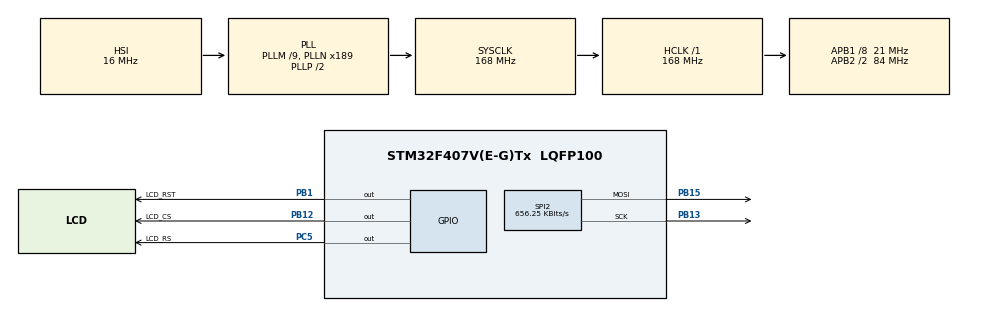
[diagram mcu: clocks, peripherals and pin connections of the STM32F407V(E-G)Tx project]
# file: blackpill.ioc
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Mcu.Family=STM32F4
Mcu.Name=STM32F407V(E-G)Tx
Mcu.Package=LQFP100
NVIC.PriorityGroup=NVIC_PRIORITYGROUP_4
NVIC.TIM8_TRG_COM_TIM14_IRQn=true\:15\:0\:false\:false\:true\:false\:true\:true
NVIC.TimeBase=TIM8_TRG_COM_TIM14_IRQn
NVIC.TimeBaseIP=TIM14
PB1.GPIO_Label=LCD_RST
PB1.GPIO_Speed=GPIO_SPEED_FREQ_VERY_HIGH
PB1.Signal=GPIO_Output
PB12.GPIO_Label=LCD_CS
PB12.GPIO_Speed=GPIO_SPEED_FREQ_VERY_HIGH
PB12.Signal=GPIO_Output
PB13.Mode=TX_Only_Simplex_Unidirect_Master
PB13.Signal=SPI2_SCK
PB15.Mode=TX_Only_Simplex_Unidirect_Master
PB15.Signal=SPI2_MOSI
PC5.GPIO_Label=LCD_RS
PC5.GPIO_Speed=GPIO_SPEED_FREQ_VERY_HIGH
PC5.Signal=GPIO_Output
ProjectManager.HeapSize=0x200
ProjectManager.StackSize=0x400
ProjectManager.TargetToolchain=STM32CubeIDE
RCC.48MHZClocksFreq_Value=84000000
RCC.AHBFreq_Value=168000000
RCC.APB1CLKDivider=RCC_HCLK_DIV8
RCC.APB1Freq_Value=21000000
RCC.APB1TimFreq_Value=42000000
RCC.APB2CLKDivider=RCC_HCLK_DIV2
RCC.APB2Freq_Value=84000000
RCC.APB2TimFreq_Value=168000000
RCC.CortexFreq_Value=168000000
RCC.HCLKFreq_Value=168000000
RCC.HSE_VALUE=25000000
RCC.HSI_VALUE=16000000
RCC.LSE_VALUE=32768
RCC.PLLM=9
RCC.PLLN=189
RCC.SYSCLKFreq_VALUE=168000000
RCC.SYSCLKSource=RCC_SYSCLKSOURCE_PLLCLK
RCC.VCOOutputFreq_Value=336000000
SPI2.BaudRatePrescaler=SPI_BAUDRATEPRESCALER_32
SPI2.CLKPolarity=SPI_POLARITY_LOW
SPI2.CalculateBaudRate=656.25 KBits/s
SPI2.Direction=SPI_DIRECTION_2LINES
SPI2.FirstBit=SPI_FIRSTBIT_MSB
SPI2.Mode=SPI_MODE_MASTER
SPI2.VirtualType=VM_MASTER
VP_SYS_VS_tim14.Mode=TIM14
VP_TIM13_VS_ClockSourceINT.Mode=Enable_Timer
board=custom

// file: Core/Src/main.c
/* USER CODE BEGIN Header */
/**
  ******************************************************************************
  * @file           : main.c
  * @brief          : Main program body
  ******************************************************************************
  * @attention
  *
  * Copyright (c) 2022 STMicroelectronics.
  * All rights reserved.
  *
  * This software is licensed under terms that can be found in the LICENSE file
  * in the root directory of this software component.
  * If no LICENSE file comes with this software, it is provided AS-IS.
  *
  ******************************************************************************
  */
/* USER CODE END Header */
#include "main.h"
#include "spi.h"
#include "tim.h"
#include "gpio.h"

/* USER CODE BEGIN Includes */
#include "st7735.h"
#include "fonts.h"
#include "stdlib.h"
/* USER CODE END Includes */

void SystemClock_Config(void);

int main(void)
{

  /* MCU Configuration--------------------------------------------------------*/

  /* Reset of all peripherals, Initializes the Flash interface and the Systick. */
  HAL_Init();

  /* Configure the system clock */
  SystemClock_Config();

  /* Initialize all configured peripherals */
  MX_GPIO_Init();
  MX_TIM13_Init();
  MX_SPI2_Init();
  /* USER CODE BEGIN 2 */

  ST7735_Init();
  ST7735_FillScreen(ST7735_RED);
  /* USER CODE END 2 */

  /* Infinite loop */
  /* USER CODE BEGIN WHILE */
  uint8_t n = 0;
  char str[10] = { 0 };
  while (1)
  {
    /* USER CODE END WHILE */
    /* USER CODE BEGIN 3 */
	  itoa(n,str,10);
	  ST7735_WriteString(0, 0, str, Font_11x18, ST7735_BLACK, ST7735_WHITE);
	  n++;
  }
  /* USER CODE END 3 */
}

void SystemClock_Config(void)
{
  RCC_OscInitTypeDef RCC_OscInitStruct = {0};
  RCC_ClkInitTypeDef RCC_ClkInitStruct = {0};

  /** Configure the main internal regulator output voltage
  */
  __HAL_RCC_PWR_CLK_ENABLE();
  __HAL_PWR_VOLTAGESCALING_CONFIG(PWR_REGULATOR_VOLTAGE_SCALE1);

  /** Initializes the RCC Oscillators according to the specified parameters
  * in the RCC_OscInitTypeDef structure.
  */
  RCC_OscInitStruct.OscillatorType = RCC_OSCILLATORTYPE_HSI;
  RCC_OscInitStruct.HSIState = RCC_HSI_ON;
  RCC_OscInitStruct.HSICalibrationValue = RCC_HSICALIBRATION_DEFAULT;
  RCC_OscInitStruct.PLL.PLLState = RCC_PLL_ON;
  RCC_OscInitStruct.PLL.PLLSource = RCC_PLLSOURCE_HSI;
  RCC_OscInitStruct.PLL.PLLM = 9;
  RCC_OscInitStruct.PLL.PLLN = 189;
  RCC_OscInitStruct.PLL.PLLP = RCC_PLLP_DIV2;
  RCC_OscInitStruct.PLL.PLLQ = 4;
  if (HAL_RCC_OscConfig(&RCC_OscInitStruct) != HAL_OK)
  {
    Error_Handler();
  }

  /** Initializes the CPU, AHB and APB buses clocks
  */
  RCC_ClkInitStruct.ClockType = RCC_CLOCKTYPE_HCLK|RCC_CLOCKTYPE_SYSCLK
                              |RCC_CLOCKTYPE_PCLK1|RCC_CLOCKTYPE_PCLK2;
  RCC_ClkInitStruct.SYSCLKSource = RCC_SYSCLKSOURCE_PLLCLK;
  RCC_ClkInitStruct.AHBCLKDivider = RCC_SYSCLK_DIV1;
  RCC_ClkInitStruct.APB1CLKDivider = RCC_HCLK_DIV8;
  RCC_ClkInitStruct.APB2CLKDivider = RCC_HCLK_DIV2;

  if (HAL_RCC_ClockConfig(&RCC_ClkInitStruct, FLASH_LATENCY_5) != HAL_OK)
  {
    Error_Handler();
  }
}

void HAL_TIM_PeriodElapsedCallback(TIM_HandleTypeDef *htim)
{
  if (htim->Instance == TIM14) {
    HAL_IncTick();
  }
}

void Error_Handler(void)
{
  __disable_irq();
  while (1)
  {
  }
}
